# ATmega645A device description
Architecture: AVR8; Family: megaAVR
Registers are 8-bit, access not given, no defined reset value unless marked. A register's access mark holds for its fields unless they carry their own. Offsets are from the block's base; [hi:lo] are bit positions.

## TC1 (TC16 module) — Timer/Counter, 16-bit
Instances: TC1 0x00
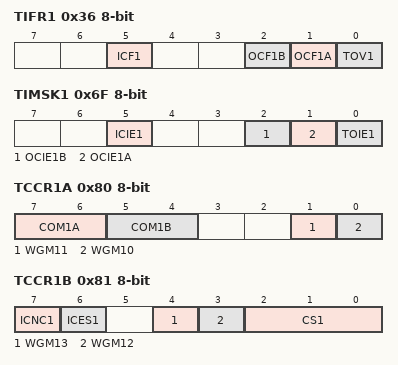
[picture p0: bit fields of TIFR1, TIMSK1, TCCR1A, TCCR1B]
0x36 TIFR1 — Timer/Counter1 Interrupt Flag register
  [5] ICF1 — Input Capture Flag 1
  [2] OCF1B — Output Compare Flag 1B
  [1] OCF1A — Output Compare Flag 1A
  [0] TOV1 — Timer/Counter1 Overflow Flag
0x6F TIMSK1 — Timer/Counter1 Interrupt Mask Register
  [5] ICIE1 — Timer/Counter1 Input Capture Interrupt Enable
  [2] OCIE1B — Timer/Counter1 Output Compare B Match Interrupt Enable
  [1] OCIE1A — Timer/Counter1 Output Compare A Match Interrupt Enable
  [0] TOIE1 — Timer/Counter1 Overflow Interrupt Enable
0x80 TCCR1A — Timer/Counter1 Control Register A
  [7:6] COM1A — Compare Output Mode 1A, bits
  [5:4] COM1B — Compare Output Mode 1B, bits
  [1] WGM11 — Waveform Generation Mode
  [0] WGM10 — Waveform Generation Mode
0x81 TCCR1B — Timer/Counter1 Control Register B
  [7] ICNC1 — Input Capture 1 Noise Canceler
  [6] ICES1 — Input Capture 1 Edge Select
  [4] WGM13 (bit 2 of the value upward) — Waveform Generation Mode
  [3] WGM12 (bit 2 of the value upward) — Waveform Generation Mode
  [2:0] CS1 — Prescaler source of Timer/Counter 1
    0=No Clock Source (Stopped); 1=Running, No Prescaling; 2=Running, CLK/8; 3=Running, CLK/64; 4=Running, CLK/256; 5=Running, CLK/1024; 6=Running, ExtClk Tx Falling Edge; 7=Running, ExtClk Tx Rising Edge
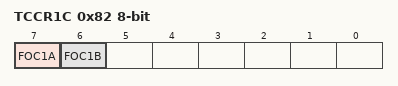
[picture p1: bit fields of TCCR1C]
0x82 TCCR1C — Timer/Counter 1 Control Register C
  [7] FOC1A — Force Output Compare 1A
  [6] FOC1B — Force Output Compare 1B
0x84 TCNT1 16-bit — Timer/Counter1 Bytes
0x86 ICR1 16-bit — Timer/Counter1 Input Capture Register Bytes
0x88 OCR1A 16-bit — Timer/Counter1 Output Compare Register A Bytes
0x8A OCR1B 16-bit — Timer/Counter1 Output Compare Register B Bytes

## WDT — Watchdog Timer
Instances: WDT 0x00
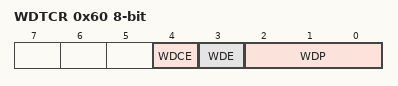
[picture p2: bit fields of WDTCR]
0x60 WDTCR — Watchdog Timer Control Register
  [4] WDCE — Watchdog Change Enable
  [3] WDE — Watch Dog Enable
  [2:0] WDP — Watch Dog Timer Prescaler bits
    0=Oscillator Cycles 16K; 1=Oscillator Cycles 32K; 2=Oscillator Cycles 64K; 3=Oscillator Cycles 128K; 4=Oscillator Cycles 256K; 5=Oscillator Cycles 512K; 6=Oscillator Cycles 1024K; 7=Oscillator Cycles 2048K

## BOOT_LOAD — Bootloader
Instances: BOOT_LOAD 0x00
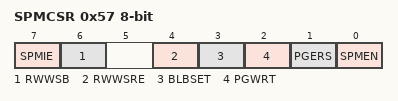
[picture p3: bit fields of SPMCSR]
0x57 SPMCSR — Store Program Memory Control Register
  [7] SPMIE — SPM Interrupt Enable
  [6] RWWSB — Read While Write Section Busy
  [4] RWWSRE — Read While Write section read enable
  [3] BLBSET — Boot Lock Bit Set
  [2] PGWRT — Page Write
  [1] PGERS — Page Erase
  [0] SPMEN — Store Program Memory Enable

## USART0 — USART
Instances: USART0 0x00
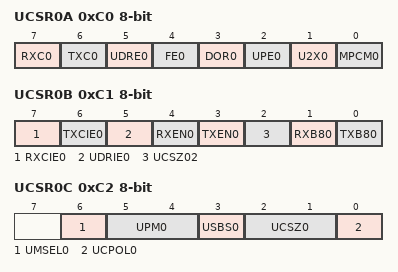
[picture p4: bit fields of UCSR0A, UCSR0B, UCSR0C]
0xC0 UCSR0A — USART Control and Status Register A
  [7] RXC0 — USART Receive Complete
  [6] TXC0 — USART Transmit Complete
  [5] UDRE0 — USART Data Register Empty
  [4] FE0 — Framing Error
  [3] DOR0 — Data OverRun
  [2] UPE0 — USART Parity Error
  [1] U2X0 — Double the USART Transmission Speed
  [0] MPCM0 — Multi-processor Communication Mode
0xC1 UCSR0B — USART Control and Status Register B
  [7] RXCIE0 — RX Complete Interrupt Enable
  [6] TXCIE0 — TX Complete Interrupt Enable
  [5] UDRIE0 — USART Data Register Empty Interrupt Enable
  [4] RXEN0 — Receiver Enable
  [3] TXEN0 — Transmitter Enable
  [2] UCSZ02 — Character Size
  [1] RXB80 — Receive Data Bit 8
  [0] TXB80 — Transmit Data Bit 8
0xC2 UCSR0C — USART Control and Status Register C
  [6] UMSEL0 — USART Mode Select
    0=Asynchronous Operation; 1=Synchronous Operation
  [5:4] UPM0 — Parity Mode Bits
    0=Disabled; 2=Enabled, Even Parity; 3=Enabled, Odd Parity
  [3] USBS0 — Stop Bit Select
    0=1-bit; 1=2-bit
  [2:1] UCSZ0 — Character Size
  [0] UCPOL0 — Clock Polarity
0xC4 UBRR0 16-bit bits used 11:0 — USART Baud Rate Register Bytes
0xC6 UDR0 — USART I/O Data Register
